# STM32G441VBT7 register map
File version: 1.0
Registers are 32-bit, access not given, reset 0x0 unless marked. A register's access mark holds for its fields unless they carry their own. Offsets are from the block's base; [hi:lo] are bit positions; {n}, {i} and the like mark numbered series; 'fields as' and 'values as' point back to an identical list.

## EXTI
Base 0x40010400
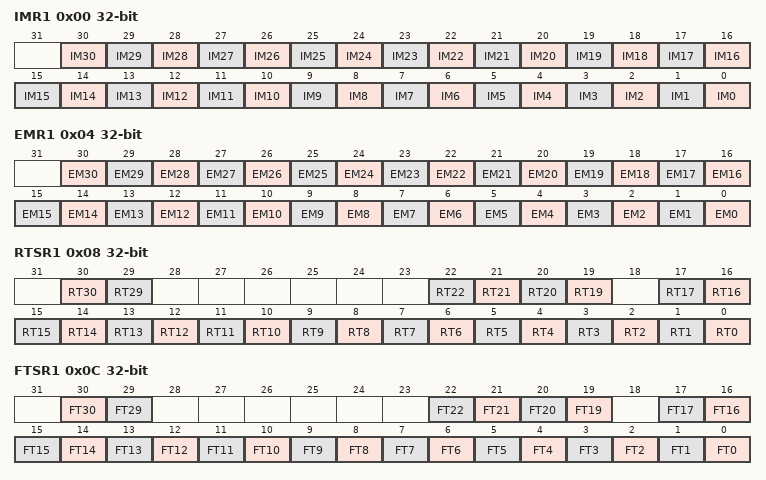
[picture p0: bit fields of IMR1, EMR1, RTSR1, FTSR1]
0x00 IMR1
  [n] IM{n} (n=0..30)
0x04 EMR1
  [n] EM{n} (n=0..30)
0x08 RTSR1
  [30] RT30, [29] RT29, [n] RT{n} (n=19..22), [n] RT{n} (n=0..17)
0x0C FTSR1
  [30] FT30, [29] FT29, [n] FT{n} (n=19..22), [n] FT{n} (n=0..17)
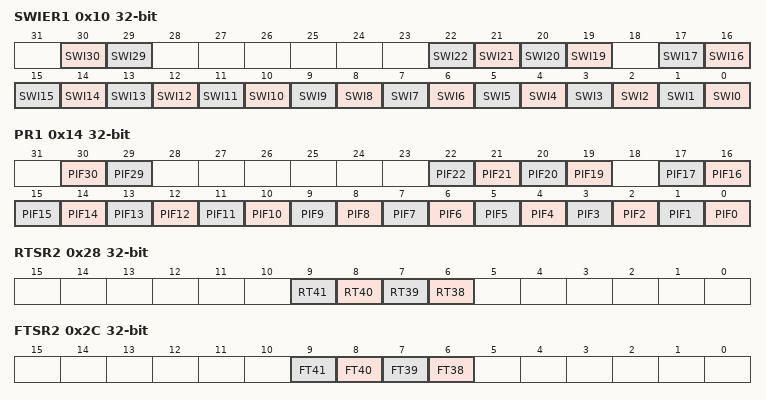
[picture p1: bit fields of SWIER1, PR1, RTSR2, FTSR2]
0x10 SWIER1
  [30] SWI30, [29] SWI29, [n] SWI{n} (n=19..22), [n] SWI{n} (n=0..17)
0x14 PR1
  [30] PIF30, [29] PIF29, [n] PIF{n} (n=19..22), [n] PIF{n} (n=0..17)
0x20 IMR2
  [n-32] IM{n} (n=36..41), [2] IM34, [9:0] IM
0x24 EMR2
  [n-32] EM{n} (n=36..41), [2] EM34, [9:0] EM
0x28 RTSR2
  [n-32] RT{n} (n=38..41)
0x2C FTSR2
  [n-32] FT{n} (n=38..41)
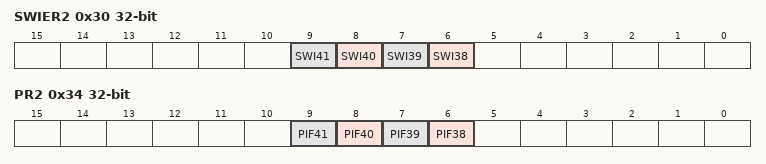
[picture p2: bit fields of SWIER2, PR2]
0x30 SWIER2
  [n-32] SWI{n} (n=38..41)
0x34 PR2
  [n-32] PIF{n} (n=38..41)

## SAI1
Base 0x40015400
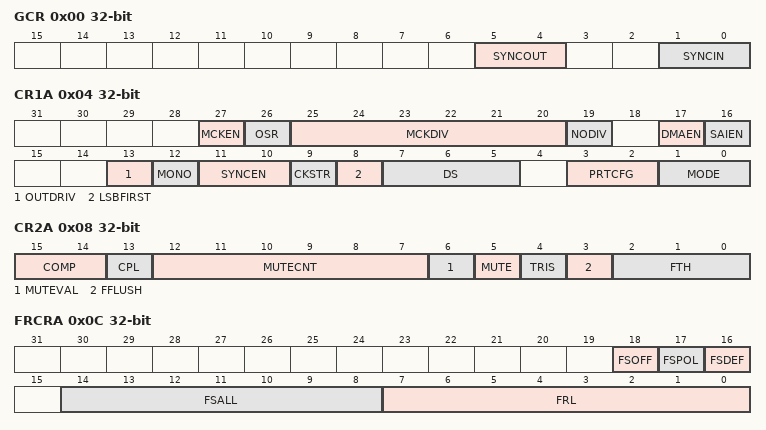
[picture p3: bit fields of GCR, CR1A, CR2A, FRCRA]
0x00 GCR
  [5:4] SYNCOUT, [1:0] SYNCIN
0x04 CR1A
  [27] MCKEN, [26] OSR, [25:20] MCKDIV, [19] NODIV, [17] DMAEN, [16] SAIEN, [13] OUTDRIV, [12] MONO, [11:10] SYNCEN, [9] CKSTR, [8] LSBFIRST, [7:5] DS, [3:2] PRTCFG, [1:0] MODE
0x08 CR2A
  [15:14] COMP, [13] CPL, [12:7] MUTECNT, [6] MUTEVAL, [5] MUTE, [4] TRIS, [3] FFLUSH, [2:0] FTH
0x0C FRCRA
  [18] FSOFF, [17] FSPOL, [16] FSDEF, [14:8] FSALL, [7:0] FRL
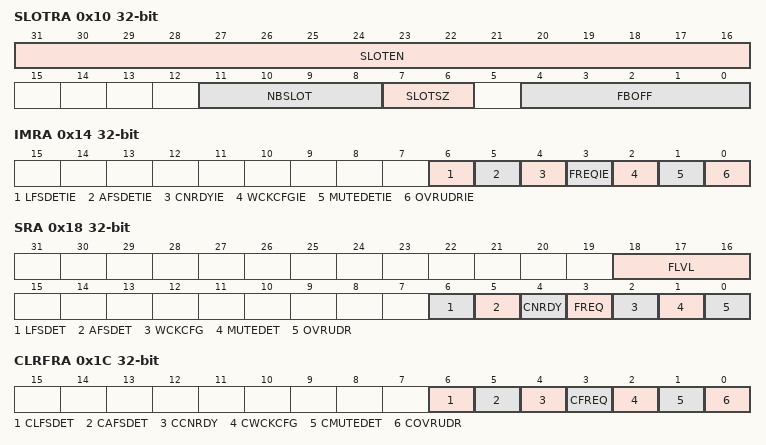
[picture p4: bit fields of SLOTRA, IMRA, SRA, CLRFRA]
0x10 SLOTRA
  [31:16] SLOTEN, [11:8] NBSLOT, [7:6] SLOTSZ, [4:0] FBOFF
0x14 IMRA
  [6] LFSDETIE, [5] AFSDETIE, [4] CNRDYIE, [3] FREQIE, [2] WCKCFGIE, [1] MUTEDETIE, [0] OVRUDRIE
0x18 SRA
  [18:16] FLVL, [6] LFSDET, [5] AFSDET, [4] CNRDY, [3] FREQ, [2] WCKCFG, [1] MUTEDET, [0] OVRUDR
0x1C CLRFRA
  [6] CLFSDET, [5] CAFSDET, [4] CCNRDY, [3] CFREQ, [2] CWCKCFG, [1] CMUTEDET, [0] COVRUDR
0x20 DRA
  [31:0] DATA
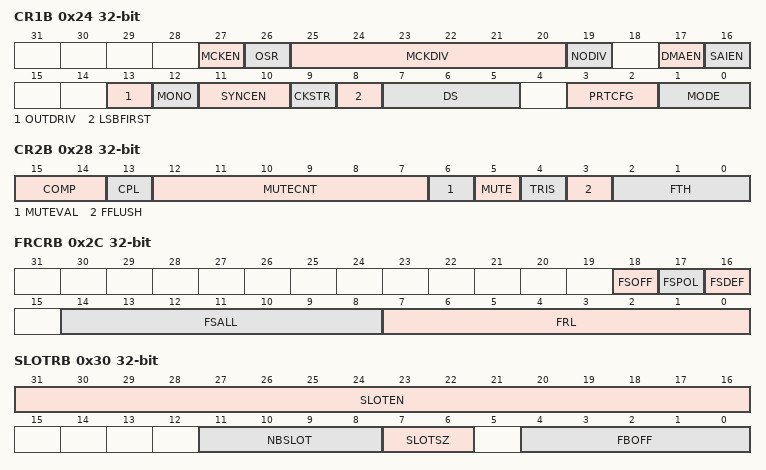
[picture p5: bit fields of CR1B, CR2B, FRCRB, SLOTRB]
0x24 CR1B
  fields as CR1A
0x28 CR2B
  fields as CR2A
0x2C FRCRB
  [18] FSOFF, [17] FSPOL, [16] FSDEF, [14:8] FSALL, [7:0] FRL
0x30 SLOTRB
  [31:16] SLOTEN, [11:8] NBSLOT, [7:6] SLOTSZ, [4:0] FBOFF
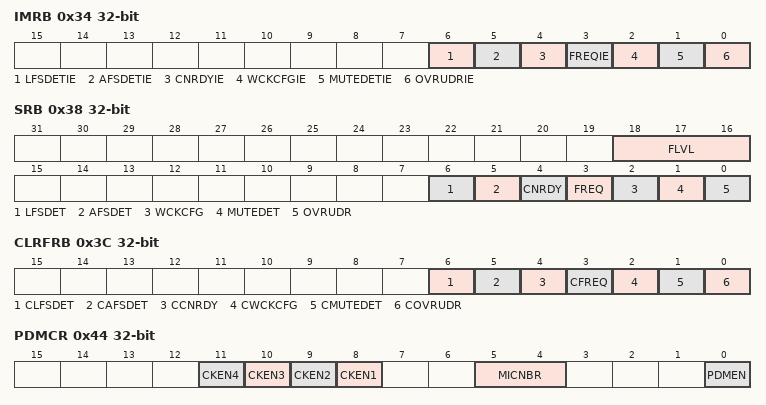
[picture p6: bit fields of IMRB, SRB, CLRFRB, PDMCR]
0x34 IMRB
  fields as IMRA
0x38 SRB
  fields as SRA
0x3C CLRFRB
  fields as CLRFRA
0x40 DRB
  [31:0] DATA
0x44 PDMCR
  [n+7] CKEN{n} (n=1..4), [5:4] MICNBR, [0] PDMEN
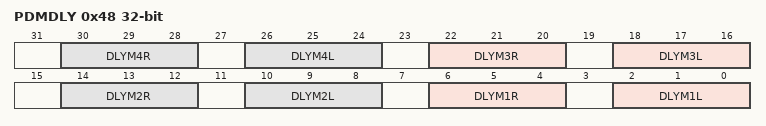
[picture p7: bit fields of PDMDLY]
0x48 PDMDLY
  [8n-2:8n-4] DLYM{n}R (n=1..4), [8n-6:8n-8] DLYM{n}L (n=1..4)

## DMA1
Base 0x40020000
Same registers: DMA2 0x40020400
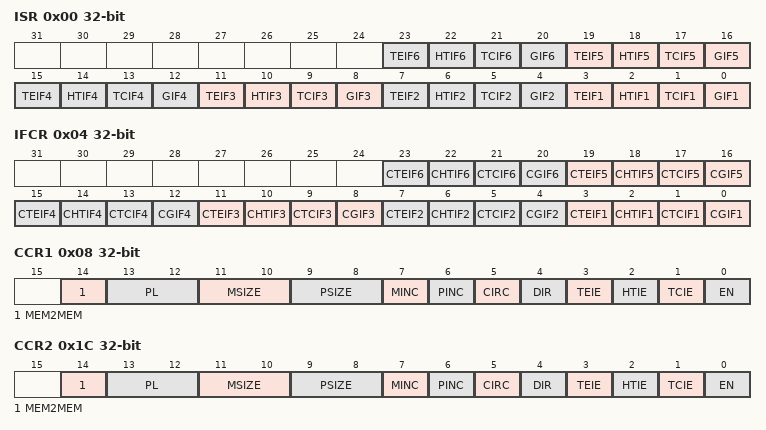
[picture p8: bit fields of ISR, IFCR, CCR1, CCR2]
0x00 ISR
  [4n-1] TEIF{n} (n=1..6), [4n-2] HTIF{n} (n=1..6), [4n-3] TCIF{n} (n=1..6), [4n-4] GIF{n} (n=1..6)
0x04 IFCR
  [4n-1] CTEIF{n} (n=1..6), [4n-2] CHTIF{n} (n=1..6), [4n-3] CTCIF{n} (n=1..6), [4n-4] CGIF{n} (n=1..6)
0x08 CCR1
  [14] MEM2MEM, [13:12] PL, [11:10] MSIZE, [9:8] PSIZE, [7] MINC, [6] PINC, [5] CIRC, [4] DIR, [3] TEIE, [2] HTIE, [1] TCIE, [0] EN
0x0C CNDTR1
  [15:0] NDT
0x10 CPAR1
  [31:0] PA
{0x0+0x14*i} CMAR{i} (i=1..6)
  [31:0] MA
0x1C CCR2
  fields as CCR1
0x20 CNDTR2
  [15:0] NDT
0x24 CPAR2
  [31:0] PA
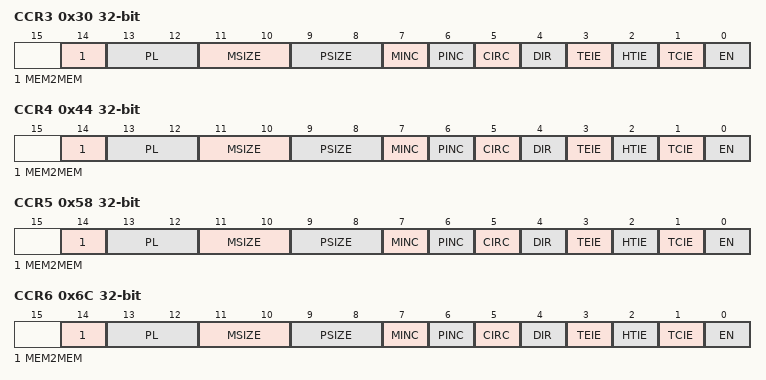
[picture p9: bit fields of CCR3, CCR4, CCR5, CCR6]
0x30 CCR3
  fields as CCR1
0x34 CNDTR3
  [15:0] NDT
0x38 CPAR3
  [31:0] PA
0x44 CCR4
  fields as CCR1
0x48 CNDTR4
  [15:0] NDT
0x4C CPAR4
  [31:0] PA
0x58 CCR5
  fields as CCR1
0x5C CNDTR5
  [15:0] NDT
0x60 CPAR5
  [31:0] PA
0x6C CCR6
  fields as CCR1
0x70 CNDTR6
  [15:0] NDT
0x74 CPAR6
  [31:0] PA

## DMAMUX1
Base 0x40020800
0x00 CCR0
0x04 CCR1
0x08 CCR2
0x0C CCR3
0x10 CCR4
0x14 CCR5
{0x8+4i} CCR{i} (i=6..9)
0x30 CCR0
0x34 CCR1
0x80 CCRs
0x100 CCR0
0x104 CCR1
0x108 CCR2
0x10C CCR3
0x140 CCRs

## CORDIC
Base 0x40020C00
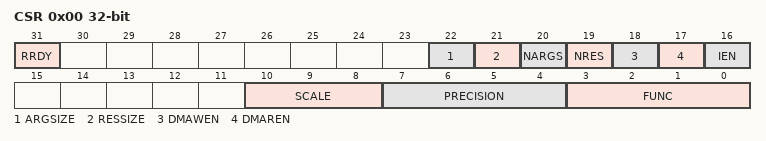
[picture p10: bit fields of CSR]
0x00 CSR
  [31] RRDY, [22] ARGSIZE, [21] RESSIZE, [20] NARGS, [19] NRES, [18] DMAWEN, [17] DMAREN, [16] IEN, [10:8] SCALE, [7:4] PRECISION, [3:0] FUNC
0x04 WDATA
  [31:0] ARG
0x08 RDATA
  [31:0] RES

## FMAC
Base 0x40021400
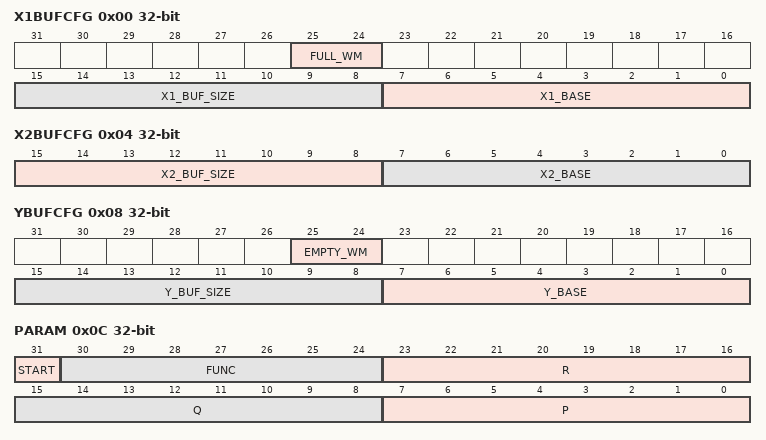
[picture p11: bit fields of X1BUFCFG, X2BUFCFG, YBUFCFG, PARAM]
0x00 X1BUFCFG
  [25:24] FULL_WM, [15:8] X1_BUF_SIZE, [7:0] X1_BASE
0x04 X2BUFCFG
  [15:8] X2_BUF_SIZE, [7:0] X2_BASE
0x08 YBUFCFG
  [25:24] EMPTY_WM, [15:8] Y_BUF_SIZE, [7:0] Y_BASE
0x0C PARAM
  [31] START, [30:24] FUNC, [23:16] R, [15:8] Q, [7:0] P
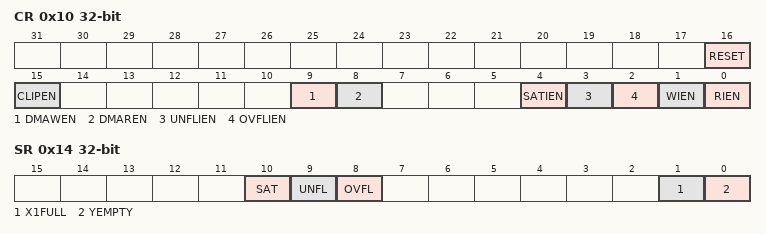
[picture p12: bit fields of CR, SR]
0x10 CR
  [16] RESET, [15] CLIPEN, [9] DMAWEN, [8] DMAREN, [4] SATIEN, [3] UNFLIEN, [2] OVFLIEN, [1] WIEN, [0] RIEN
0x14 SR
  [10] SAT, [9] UNFL, [8] OVFL, [1] X1FULL, [0] YEMPTY
0x18 WDATA
  [15:0] WDATA
0x1C RDATA
  [15:0] RDATA
